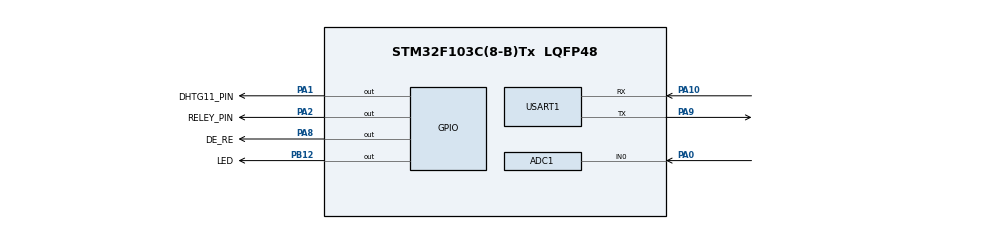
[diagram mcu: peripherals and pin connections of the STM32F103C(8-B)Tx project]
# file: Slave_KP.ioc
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ADC1.Channel-0\#ChannelRegularConversion=ADC_CHANNEL_0
ADC1.NbrOfConversionFlag=1
ADC1.Rank-0\#ChannelRegularConversion=1
ADC1.SamplingTime-0\#ChannelRegularConversion=ADC_SAMPLETIME_1CYCLE_5
ADC1.master=1
Mcu.Family=STM32F1
Mcu.Name=STM32F103C(8-B)Tx
Mcu.Package=LQFP48
NVIC.PriorityGroup=NVIC_PRIORITYGROUP_4
NVIC.USART1_IRQn=true\:0\:0\:false\:false\:true\:true\:true\:true
PA0-WKUP.Signal=ADCx_IN0
PA1.GPIO_Label=DHTG11_PIN
PA1.Signal=GPIO_Output
PA10.Mode=Asynchronous
PA10.Signal=USART1_RX
PA13.Mode=Serial_Wire
PA13.Signal=SYS_JTMS-SWDIO
PA14.Mode=Serial_Wire
PA14.Signal=SYS_JTCK-SWCLK
PA2.GPIO_Label=RELEY_PIN
PA2.Signal=GPIO_Output
PA8.GPIO_Label=DE_RE
PA8.Signal=GPIO_Output
PA9.Mode=Asynchronous
PA9.Signal=USART1_TX
PB12.GPIO_Label=LED
PB12.Signal=GPIO_Output
ProjectManager.HeapSize=0x200
ProjectManager.StackSize=0x400
ProjectManager.TargetToolchain=STM32CubeIDE
RCC.APB1Freq_Value=8000000
RCC.APB2Freq_Value=8000000
SH.ADCx_IN0.0=ADC1_IN0,IN0
USART1.VirtualMode=VM_ASYNC
board=custom

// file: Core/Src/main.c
/* USER CODE BEGIN Header */
/**
  ******************************************************************************
  * @file           : main.c
  * @brief          : Main program body
  ******************************************************************************
  * @attention
  *
  * Copyright (c) 2026 STMicroelectronics.
  * All rights reserved.
  *
  * This software is licensed under terms that can be found in the LICENSE file
  * in the root directory of this software component.
  * If no LICENSE file comes with this software, it is provided AS-IS.
  *
  ******************************************************************************
  */
/* USER CODE END Header */
#include "main.h"
#include "adc.h"
#include "usart.h"
#include "gpio.h"

/* USER CODE BEGIN PV */
uint8_t rx_uart_byte;
uint8_t rx_buffer[64];
uint16_t rx_index = 0;
/* USER CODE END PV */

void SystemClock_Config(void);

int main(void)
{

  /* MCU Configuration--------------------------------------------------------*/

  /* Reset of all peripherals, Initializes the Flash interface and the Systick. */
  HAL_Init();

  /* Configure the system clock */
  SystemClock_Config();

  /* Initialize all configured peripherals */
  MX_GPIO_Init();
  MX_ADC1_Init();
  MX_USART1_UART_Init();

  /* Infinite loop */
  while (1)
  {

  }
}

void SystemClock_Config(void)
{
  RCC_OscInitTypeDef RCC_OscInitStruct = {0};
  RCC_ClkInitTypeDef RCC_ClkInitStruct = {0};
  RCC_PeriphCLKInitTypeDef PeriphClkInit = {0};

  /** Initializes the RCC Oscillators according to the specified parameters
  * in the RCC_OscInitTypeDef structure.
  */
  RCC_OscInitStruct.OscillatorType = RCC_OSCILLATORTYPE_HSI;
  RCC_OscInitStruct.HSIState = RCC_HSI_ON;
  RCC_OscInitStruct.HSICalibrationValue = RCC_HSICALIBRATION_DEFAULT;
  RCC_OscInitStruct.PLL.PLLState = RCC_PLL_NONE;
  if (HAL_RCC_OscConfig(&RCC_OscInitStruct) != HAL_OK)
  {
    Error_Handler();
  }

  /** Initializes the CPU, AHB and APB buses clocks
  */
  RCC_ClkInitStruct.ClockType = RCC_CLOCKTYPE_HCLK|RCC_CLOCKTYPE_SYSCLK
                              |RCC_CLOCKTYPE_PCLK1|RCC_CLOCKTYPE_PCLK2;
  RCC_ClkInitStruct.SYSCLKSource = RCC_SYSCLKSOURCE_HSI;
  RCC_ClkInitStruct.AHBCLKDivider = RCC_SYSCLK_DIV1;
  RCC_ClkInitStruct.APB1CLKDivider = RCC_HCLK_DIV1;
  RCC_ClkInitStruct.APB2CLKDivider = RCC_HCLK_DIV1;

  if (HAL_RCC_ClockConfig(&RCC_ClkInitStruct, FLASH_LATENCY_0) != HAL_OK)
  {
    Error_Handler();
  }
  PeriphClkInit.PeriphClockSelection = RCC_PERIPHCLK_ADC;
  PeriphClkInit.AdcClockSelection = RCC_ADCPCLK2_DIV2;
  if (HAL_RCCEx_PeriphCLKConfig(&PeriphClkInit) != HAL_OK)
  {
    Error_Handler();
  }
}

/* USER CODE BEGIN 4 */
void HAL_UART_RxCpltCallback(UART_HandleTypeDef *huart) {
    if (huart->Instance == USART1) {
        if (rx_index < 64) {
            rx_buffer[rx_index++] = rx_uart_byte;
        }

        // Gọi lại ngắt nhận byte tiếp theo
        HAL_UART_Receive_IT(&huart1, &rx_uart_byte, 1);
    }
}
/* USER CODE END 4 */

void Error_Handler(void)
{
  __disable_irq();
  while (1)
  {
  }
}
